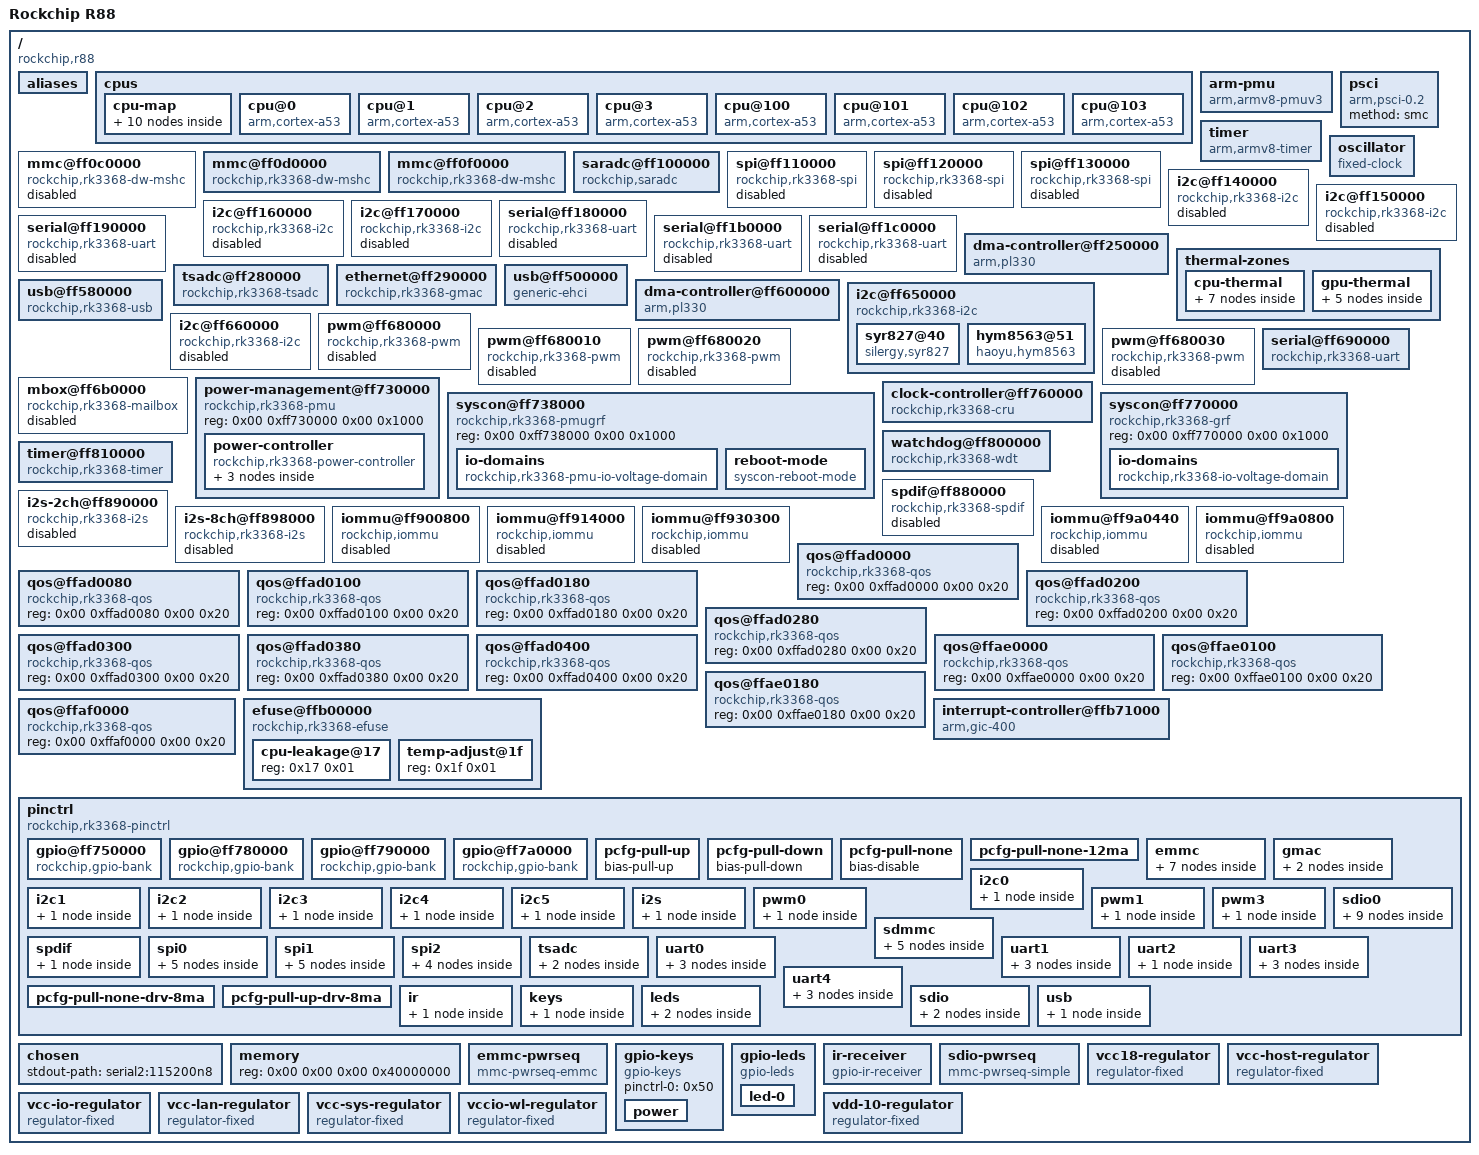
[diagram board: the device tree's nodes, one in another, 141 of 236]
/dts-v1/;

/ {
	compatible = "rockchip,r88\0rockchip,rk3368";
	interrupt-parent = <0x01>;
	#address-cells = <0x02>;
	#size-cells = <0x02>;
	model = "Rockchip R88";

	aliases {
		ethernet0 = "/ethernet@ff290000";
		i2c0 = "/i2c@ff650000";
		i2c1 = "/i2c@ff660000";
		i2c2 = "/i2c@ff140000";
		i2c3 = "/i2c@ff150000";
		i2c4 = "/i2c@ff160000";
		i2c5 = "/i2c@ff170000";
		serial0 = "/serial@ff180000";
		serial1 = "/serial@ff190000";
		serial2 = "/serial@ff690000";
		serial3 = "/serial@ff1b0000";
		serial4 = "/serial@ff1c0000";
		spi0 = "/spi@ff110000";
		spi1 = "/spi@ff120000";
		spi2 = "/spi@ff130000";
		mmc0 = "/mmc@ff0d0000";
		mmc1 = "/mmc@ff0f0000";
	};

	cpus {
		#address-cells = <0x02>;
		#size-cells = <0x00>;

		cpu-map {

			cluster0 {

				core0 {
					cpu = <0x02>;
				};

				core1 {
					cpu = <0x03>;
				};

				core2 {
					cpu = <0x04>;
				};

				core3 {
					cpu = <0x05>;
				};
			};

			cluster1 {

				core0 {
					cpu = <0x06>;
				};

				core1 {
					cpu = <0x07>;
				};

				core2 {
					cpu = <0x08>;
				};

				core3 {
					cpu = <0x09>;
				};
			};
		};

		cpu@0 {
			device_type = "cpu";
			compatible = "arm,cortex-a53";
			reg = <0x00 0x00>;
			enable-method = "psci";
			#cooling-cells = <0x02>;
			phandle = <0x06>;
		};

		cpu@1 {
			device_type = "cpu";
			compatible = "arm,cortex-a53";
			reg = <0x00 0x01>;
			enable-method = "psci";
			#cooling-cells = <0x02>;
			phandle = <0x07>;
		};

		cpu@2 {
			device_type = "cpu";
			compatible = "arm,cortex-a53";
			reg = <0x00 0x02>;
			enable-method = "psci";
			#cooling-cells = <0x02>;
			phandle = <0x08>;
		};

		cpu@3 {
			device_type = "cpu";
			compatible = "arm,cortex-a53";
			reg = <0x00 0x03>;
			enable-method = "psci";
			#cooling-cells = <0x02>;
			phandle = <0x09>;
		};

		cpu@100 {
			device_type = "cpu";
			compatible = "arm,cortex-a53";
			reg = <0x00 0x100>;
			enable-method = "psci";
			#cooling-cells = <0x02>;
			phandle = <0x02>;
		};

		cpu@101 {
			device_type = "cpu";
			compatible = "arm,cortex-a53";
			reg = <0x00 0x101>;
			enable-method = "psci";
			#cooling-cells = <0x02>;
			phandle = <0x03>;
		};

		cpu@102 {
			device_type = "cpu";
			compatible = "arm,cortex-a53";
			reg = <0x00 0x102>;
			enable-method = "psci";
			#cooling-cells = <0x02>;
			phandle = <0x04>;
		};

		cpu@103 {
			device_type = "cpu";
			compatible = "arm,cortex-a53";
			reg = <0x00 0x103>;
			enable-method = "psci";
			#cooling-cells = <0x02>;
			phandle = <0x05>;
		};
	};

	arm-pmu {
		compatible = "arm,armv8-pmuv3";
		interrupts = <0x00 0x70 0x04 0x00 0x71 0x04 0x00 0x72 0x04 0x00 0x73 0x04 0x00 0x74 0x04 0x00 0x75 0x04 0x00 0x76 0x04 0x00 0x77 0x04>;
		interrupt-affinity = <0x06 0x07 0x08 0x09 0x02 0x03 0x04 0x05>;
	};

	psci {
		compatible = "arm,psci-0.2";
		method = "smc";
	};

	timer {
		compatible = "arm,armv8-timer";
		interrupts = <0x01 0x0d 0xff04 0x01 0x0e 0xff04 0x01 0x0b 0xff04 0x01 0x0a 0xff04>;
	};

	oscillator {
		compatible = "fixed-clock";
		clock-frequency = <0x16e3600>;
		clock-output-names = "xin24m";
		#clock-cells = <0x00>;
		phandle = <0x58>;
	};

	mmc@ff0c0000 {
		compatible = "rockchip,rk3368-dw-mshc\0rockchip,rk3288-dw-mshc";
		reg = <0x00 0xff0c0000 0x00 0x4000>;
		max-frequency = <0x8f0d180>;
		clocks = <0x0a 0x1c8 0x0a 0x44 0x0a 0x72 0x0a 0x76>;
		clock-names = "biu\0ciu\0ciu-drive\0ciu-sample";
		fifo-depth = <0x100>;
		interrupts = <0x00 0x20 0x04>;
		resets = <0x0a 0x80>;
		reset-names = "reset";
		status = "disabled";
		phandle = <0x59>;
	};

	mmc@ff0d0000 {
		compatible = "rockchip,rk3368-dw-mshc\0rockchip,rk3288-dw-mshc";
		reg = <0x00 0xff0d0000 0x00 0x4000>;
		max-frequency = <0x8f0d180>;
		clocks = <0x0a 0x1c9 0x0a 0x45 0x0a 0x73 0x0a 0x77>;
		clock-names = "biu\0ciu\0ciu-drive\0ciu-sample";
		fifo-depth = <0x100>;
		interrupts = <0x00 0x21 0x04>;
		resets = <0x0a 0x81>;
		reset-names = "reset";
		status = "okay";
		assigned-clocks = <0x0a 0x45>;
		assigned-clock-parents = <0x0a 0x04>;
		bus-width = <0x04>;
		cap-sd-highspeed;
		cap-sdio-irq;
		keep-power-in-suspend;
		mmc-pwrseq = <0x0b>;
		non-removable;
		pinctrl-names = "default";
		pinctrl-0 = <0x0c 0x0d 0x0e>;
		vmmc-supply = <0x0f>;
		vqmmc-supply = <0x10>;
		phandle = <0x5a>;
	};

	mmc@ff0f0000 {
		compatible = "rockchip,rk3368-dw-mshc\0rockchip,rk3288-dw-mshc";
		reg = <0x00 0xff0f0000 0x00 0x4000>;
		max-frequency = <0x8f0d180>;
		clocks = <0x0a 0x1cb 0x0a 0x47 0x0a 0x75 0x0a 0x79>;
		clock-names = "biu\0ciu\0ciu-drive\0ciu-sample";
		fifo-depth = <0x100>;
		interrupts = <0x00 0x23 0x04>;
		resets = <0x0a 0x83>;
		reset-names = "reset";
		status = "okay";
		bus-width = <0x08>;
		cap-mmc-highspeed;
		mmc-pwrseq = <0x11>;
		non-removable;
		pinctrl-names = "default";
		pinctrl-0 = <0x12 0x13 0x14>;
		phandle = <0x5b>;
	};

	saradc@ff100000 {
		compatible = "rockchip,saradc";
		reg = <0x00 0xff100000 0x00 0x100>;
		interrupts = <0x00 0x24 0x04>;
		#io-channel-cells = <0x01>;
		clocks = <0x0a 0x49 0x0a 0x15b>;
		clock-names = "saradc\0apb_pclk";
		resets = <0x0a 0x57>;
		reset-names = "saradc-apb";
		status = "okay";
		vref-supply = <0x15>;
		phandle = <0x5c>;
	};

	spi@ff110000 {
		compatible = "rockchip,rk3368-spi\0rockchip,rk3066-spi";
		reg = <0x00 0xff110000 0x00 0x1000>;
		clocks = <0x0a 0x41 0x0a 0x152>;
		clock-names = "spiclk\0apb_pclk";
		interrupts = <0x00 0x2c 0x04>;
		pinctrl-names = "default";
		pinctrl-0 = <0x16 0x17 0x18 0x19>;
		#address-cells = <0x01>;
		#size-cells = <0x00>;
		status = "disabled";
		phandle = <0x5d>;
	};

	spi@ff120000 {
		compatible = "rockchip,rk3368-spi\0rockchip,rk3066-spi";
		reg = <0x00 0xff120000 0x00 0x1000>;
		clocks = <0x0a 0x42 0x0a 0x153>;
		clock-names = "spiclk\0apb_pclk";
		interrupts = <0x00 0x2d 0x04>;
		pinctrl-names = "default";
		pinctrl-0 = <0x1a 0x1b 0x1c 0x1d>;
		#address-cells = <0x01>;
		#size-cells = <0x00>;
		status = "disabled";
		phandle = <0x5e>;
	};

	spi@ff130000 {
		compatible = "rockchip,rk3368-spi\0rockchip,rk3066-spi";
		reg = <0x00 0xff130000 0x00 0x1000>;
		clocks = <0x0a 0x43 0x0a 0x154>;
		clock-names = "spiclk\0apb_pclk";
		interrupts = <0x00 0x29 0x04>;
		pinctrl-names = "default";
		pinctrl-0 = <0x1e 0x1f 0x20 0x21>;
		#address-cells = <0x01>;
		#size-cells = <0x00>;
		status = "disabled";
		phandle = <0x5f>;
	};

	i2c@ff140000 {
		compatible = "rockchip,rk3368-i2c\0rockchip,rk3288-i2c";
		reg = <0x00 0xff140000 0x00 0x1000>;
		interrupts = <0x00 0x3e 0x04>;
		#address-cells = <0x01>;
		#size-cells = <0x00>;
		clock-names = "i2c";
		clocks = <0x0a 0x14e>;
		pinctrl-names = "default";
		pinctrl-0 = <0x22>;
		status = "disabled";
		phandle = <0x60>;
	};

	i2c@ff150000 {
		compatible = "rockchip,rk3368-i2c\0rockchip,rk3288-i2c";
		reg = <0x00 0xff150000 0x00 0x1000>;
		interrupts = <0x00 0x3f 0x04>;
		#address-cells = <0x01>;
		#size-cells = <0x00>;
		clock-names = "i2c";
		clocks = <0x0a 0x14f>;
		pinctrl-names = "default";
		pinctrl-0 = <0x23>;
		status = "disabled";
		phandle = <0x61>;
	};

	i2c@ff160000 {
		compatible = "rockchip,rk3368-i2c\0rockchip,rk3288-i2c";
		reg = <0x00 0xff160000 0x00 0x1000>;
		interrupts = <0x00 0x40 0x04>;
		#address-cells = <0x01>;
		#size-cells = <0x00>;
		clock-names = "i2c";
		clocks = <0x0a 0x150>;
		pinctrl-names = "default";
		pinctrl-0 = <0x24>;
		status = "disabled";
		phandle = <0x62>;
	};

	i2c@ff170000 {
		compatible = "rockchip,rk3368-i2c\0rockchip,rk3288-i2c";
		reg = <0x00 0xff170000 0x00 0x1000>;
		interrupts = <0x00 0x41 0x04>;
		#address-cells = <0x01>;
		#size-cells = <0x00>;
		clock-names = "i2c";
		clocks = <0x0a 0x151>;
		pinctrl-names = "default";
		pinctrl-0 = <0x25>;
		status = "disabled";
		phandle = <0x63>;
	};

	serial@ff180000 {
		compatible = "rockchip,rk3368-uart\0snps,dw-apb-uart";
		reg = <0x00 0xff180000 0x00 0x100>;
		clock-frequency = <0x16e3600>;
		clocks = <0x0a 0x4d 0x0a 0x155>;
		clock-names = "baudclk\0apb_pclk";
		interrupts = <0x00 0x37 0x04>;
		reg-shift = <0x02>;
		reg-io-width = <0x04>;
		status = "disabled";
		phandle = <0x64>;
	};

	serial@ff190000 {
		compatible = "rockchip,rk3368-uart\0snps,dw-apb-uart";
		reg = <0x00 0xff190000 0x00 0x100>;
		clock-frequency = <0x16e3600>;
		clocks = <0x0a 0x4e 0x0a 0x156>;
		clock-names = "baudclk\0apb_pclk";
		interrupts = <0x00 0x38 0x04>;
		reg-shift = <0x02>;
		reg-io-width = <0x04>;
		status = "disabled";
		phandle = <0x65>;
	};

	serial@ff1b0000 {
		compatible = "rockchip,rk3368-uart\0snps,dw-apb-uart";
		reg = <0x00 0xff1b0000 0x00 0x100>;
		clock-frequency = <0x16e3600>;
		clocks = <0x0a 0x50 0x0a 0x158>;
		clock-names = "baudclk\0apb_pclk";
		interrupts = <0x00 0x3a 0x04>;
		reg-shift = <0x02>;
		reg-io-width = <0x04>;
		status = "disabled";
		phandle = <0x66>;
	};

	serial@ff1c0000 {
		compatible = "rockchip,rk3368-uart\0snps,dw-apb-uart";
		reg = <0x00 0xff1c0000 0x00 0x100>;
		clock-frequency = <0x16e3600>;
		clocks = <0x0a 0x51 0x0a 0x159>;
		clock-names = "baudclk\0apb_pclk";
		interrupts = <0x00 0x3b 0x04>;
		reg-shift = <0x02>;
		reg-io-width = <0x04>;
		status = "disabled";
		phandle = <0x67>;
	};

	dma-controller@ff250000 {
		compatible = "arm,pl330\0arm,primecell";
		reg = <0x00 0xff250000 0x00 0x4000>;
		interrupts = <0x00 0x02 0x04 0x00 0x03 0x04>;
		#dma-cells = <0x01>;
		arm,pl330-broken-no-flushp;
		arm,pl330-periph-burst;
		clocks = <0x0a 0xc3>;
		clock-names = "apb_pclk";
		phandle = <0x68>;
	};

	thermal-zones {

		cpu-thermal {
			polling-delay-passive = <0x64>;
			polling-delay = <0x1388>;
			thermal-sensors = <0x26 0x00>;
			phandle = <0x69>;

			trips {

				cpu_alert0 {
					temperature = <0x124f8>;
					hysteresis = <0x7d0>;
					type = "passive";
					phandle = <0x27>;
				};

				cpu_alert1 {
					temperature = <0x13880>;
					hysteresis = <0x7d0>;
					type = "passive";
					phandle = <0x28>;
				};

				cpu_crit {
					temperature = <0x17318>;
					hysteresis = <0x7d0>;
					type = "critical";
					phandle = <0x6a>;
				};
			};

			cooling-maps {

				map0 {
					trip = <0x27>;
					cooling-device = <0x02 0xffffffff 0xffffffff 0x03 0xffffffff 0xffffffff 0x04 0xffffffff 0xffffffff 0x05 0xffffffff 0xffffffff>;
				};

				map1 {
					trip = <0x28>;
					cooling-device = <0x06 0xffffffff 0xffffffff 0x07 0xffffffff 0xffffffff 0x08 0xffffffff 0xffffffff 0x09 0xffffffff 0xffffffff>;
				};
			};
		};

		gpu-thermal {
			polling-delay-passive = <0x64>;
			polling-delay = <0x1388>;
			thermal-sensors = <0x26 0x01>;
			phandle = <0x6b>;

			trips {

				gpu_alert0 {
					temperature = <0x13880>;
					hysteresis = <0x7d0>;
					type = "passive";
					phandle = <0x29>;
				};

				gpu_crit {
					temperature = <0x1c138>;
					hysteresis = <0x7d0>;
					type = "critical";
					phandle = <0x6c>;
				};
			};

			cooling-maps {

				map0 {
					trip = <0x29>;
					cooling-device = <0x02 0xffffffff 0xffffffff 0x03 0xffffffff 0xffffffff 0x04 0xffffffff 0xffffffff 0x05 0xffffffff 0xffffffff>;
				};
			};
		};
	};

	tsadc@ff280000 {
		compatible = "rockchip,rk3368-tsadc";
		reg = <0x00 0xff280000 0x00 0x100>;
		interrupts = <0x00 0x25 0x04>;
		clocks = <0x0a 0x48 0x0a 0x15a>;
		clock-names = "tsadc\0apb_pclk";
		resets = <0x0a 0x9f>;
		reset-names = "tsadc-apb";
		pinctrl-names = "init\0default\0sleep";
		pinctrl-0 = <0x2a>;
		pinctrl-1 = <0x2b>;
		pinctrl-2 = <0x2a>;
		#thermal-sensor-cells = <0x01>;
		rockchip,hw-tshut-temp = <0x17318>;
		status = "okay";
		rockchip,hw-tshut-mode = <0x00>;
		rockchip,hw-tshut-polarity = <0x00>;
		phandle = <0x26>;
	};

	ethernet@ff290000 {
		compatible = "rockchip,rk3368-gmac";
		reg = <0x00 0xff290000 0x00 0x10000>;
		interrupts = <0x00 0x1b 0x04>;
		interrupt-names = "macirq";
		rockchip,grf = <0x2c>;
		clocks = <0x0a 0x7f 0x0a 0x66 0x0a 0x67 0x0a 0x63 0x0a 0x80 0x0a 0xc5 0x0a 0x15d>;
		clock-names = "stmmaceth\0mac_clk_rx\0mac_clk_tx\0clk_mac_ref\0clk_mac_refout\0aclk_mac\0pclk_mac";
		status = "okay";
		phy-supply = <0x2d>;
		phy-mode = "rmii";
		clock_in_out = "output";
		snps,reset-gpio = <0x2e 0x0c 0x00>;
		snps,reset-active-low;
		snps,reset-delays-us = <0x00 0x2710 0xf4240>;
		pinctrl-names = "default";
		pinctrl-0 = <0x2f>;
		tx_delay = <0x30>;
		rx_delay = <0x10>;
		phandle = <0x6d>;
	};

	usb@ff500000 {
		compatible = "generic-ehci";
		reg = <0x00 0xff500000 0x00 0x100>;
		interrupts = <0x00 0x18 0x04>;
		clocks = <0x0a 0x1c2>;
		status = "okay";
		phandle = <0x6e>;
	};

	usb@ff580000 {
		compatible = "rockchip,rk3368-usb\0rockchip,rk3066-usb\0snps,dwc2";
		reg = <0x00 0xff580000 0x00 0x40000>;
		interrupts = <0x00 0x17 0x04>;
		clocks = <0x0a 0x1c1>;
		clock-names = "otg";
		dr_mode = "host";
		g-np-tx-fifo-size = <0x10>;
		g-rx-fifo-size = <0x113>;
		g-tx-fifo-size = <0x100 0x80 0x80 0x40 0x40 0x20>;
		status = "okay";
		phandle = <0x6f>;
	};

	dma-controller@ff600000 {
		compatible = "arm,pl330\0arm,primecell";
		reg = <0x00 0xff600000 0x00 0x4000>;
		interrupts = <0x00 0x00 0x04 0x00 0x01 0x04>;
		#dma-cells = <0x01>;
		arm,pl330-broken-no-flushp;
		arm,pl330-periph-burst;
		clocks = <0x0a 0xc2>;
		clock-names = "apb_pclk";
		phandle = <0x44>;
	};

	i2c@ff650000 {
		compatible = "rockchip,rk3368-i2c\0rockchip,rk3288-i2c";
		reg = <0x00 0xff650000 0x00 0x1000>;
		clocks = <0x0a 0x14c>;
		clock-names = "i2c";
		interrupts = <0x00 0x3c 0x04>;
		pinctrl-names = "default";
		pinctrl-0 = <0x30>;
		#address-cells = <0x01>;
		#size-cells = <0x00>;
		status = "okay";
		phandle = <0x70>;

		syr827@40 {
			compatible = "silergy,syr827";
			reg = <0x40>;
			fcs,suspend-voltage-selector = <0x01>;
			regulator-name = "vdd_cpu";
			regulator-enable-ramp-delay = <0x12c>;
			regulator-min-microvolt = <0xadf34>;
			regulator-max-microvolt = <0x16e360>;
			regulator-ramp-delay = <0x1f40>;
			regulator-always-on;
			regulator-boot-on;
			vin-supply = <0x31>;
			phandle = <0x71>;
		};

		hym8563@51 {
			compatible = "haoyu,hym8563";
			reg = <0x51>;
			#clock-cells = <0x00>;
			clock-frequency = <0x8000>;
			clock-output-names = "xin32k";
			phandle = <0x54>;
		};
	};

	i2c@ff660000 {
		compatible = "rockchip,rk3368-i2c\0rockchip,rk3288-i2c";
		reg = <0x00 0xff660000 0x00 0x1000>;
		interrupts = <0x00 0x3d 0x04>;
		#address-cells = <0x01>;
		#size-cells = <0x00>;
		clock-names = "i2c";
		clocks = <0x0a 0x14d>;
		pinctrl-names = "default";
		pinctrl-0 = <0x32>;
		status = "disabled";
		phandle = <0x72>;
	};

	pwm@ff680000 {
		compatible = "rockchip,rk3368-pwm\0rockchip,rk3288-pwm";
		reg = <0x00 0xff680000 0x00 0x10>;
		#pwm-cells = <0x03>;
		pinctrl-names = "default";
		pinctrl-0 = <0x33>;
		clocks = <0x0a 0x15f>;
		status = "disabled";
		phandle = <0x73>;
	};

	pwm@ff680010 {
		compatible = "rockchip,rk3368-pwm\0rockchip,rk3288-pwm";
		reg = <0x00 0xff680010 0x00 0x10>;
		#pwm-cells = <0x03>;
		pinctrl-names = "default";
		pinctrl-0 = <0x34>;
		clocks = <0x0a 0x15f>;
		status = "disabled";
		phandle = <0x74>;
	};

	pwm@ff680020 {
		compatible = "rockchip,rk3368-pwm\0rockchip,rk3288-pwm";
		reg = <0x00 0xff680020 0x00 0x10>;
		#pwm-cells = <0x03>;
		clocks = <0x0a 0x15f>;
		status = "disabled";
		phandle = <0x75>;
	};

	pwm@ff680030 {
		compatible = "rockchip,rk3368-pwm\0rockchip,rk3288-pwm";
		reg = <0x00 0xff680030 0x00 0x10>;
		#pwm-cells = <0x03>;
		pinctrl-names = "default";
		pinctrl-0 = <0x35>;
		clocks = <0x0a 0x15f>;
		status = "disabled";
		phandle = <0x76>;
	};

	serial@ff690000 {
		compatible = "rockchip,rk3368-uart\0snps,dw-apb-uart";
		reg = <0x00 0xff690000 0x00 0x100>;
		clocks = <0x0a 0x4f 0x0a 0x157>;
		clock-names = "baudclk\0apb_pclk";
		interrupts = <0x00 0x39 0x04>;
		pinctrl-names = "default";
		pinctrl-0 = <0x36>;
		reg-shift = <0x02>;
		reg-io-width = <0x04>;
		status = "okay";
		phandle = <0x77>;
	};

	mbox@ff6b0000 {
		compatible = "rockchip,rk3368-mailbox";
		reg = <0x00 0xff6b0000 0x00 0x1000>;
		interrupts = <0x00 0x92 0x04 0x00 0x93 0x04 0x00 0x94 0x04 0x00 0x95 0x04>;
		clocks = <0x0a 0x145>;
		clock-names = "pclk_mailbox";
		#mbox-cells = <0x01>;
		status = "disabled";
		phandle = <0x78>;
	};

	power-management@ff730000 {
		compatible = "rockchip,rk3368-pmu\0syscon\0simple-mfd";
		reg = <0x00 0xff730000 0x00 0x1000>;
		phandle = <0x79>;

		power-controller {
			compatible = "rockchip,rk3368-power-controller";
			#power-domain-cells = <0x01>;
			#address-cells = <0x01>;
			#size-cells = <0x00>;
			phandle = <0x47>;

			power-domain@12 {
				reg = <0x0c>;
				clocks = <0x0a 0xca 0x0a 0xcd 0x0a 0xcc 0x0a 0xc8 0x0a 0xc6 0x0a 0xc7 0x0a 0xbe 0x0a 0x1d4 0x0a 0x1d5 0x0a 0x1d6 0x0a 0x1d9 0x0a 0x1d1 0x0a 0x1db 0x0a 0x163 0x0a 0x168 0x0a 0x167 0x0a 0x16e 0x0a 0x16f 0x0a 0x172 0x0a 0x173 0x0a 0x166 0x0a 0x164 0x0a 0x64 0x0a 0x68 0x0a 0x69 0x0a 0x6c 0x0a 0x6b 0x0a 0x6a 0x0a 0x6e 0x0a 0x6d>;
				pm_qos = <0x37 0x38 0x39 0x3a 0x3b 0x3c 0x3d 0x3e 0x3f>;
				#power-domain-cells = <0x00>;
			};

			power-domain@14 {
				reg = <0x0e>;
				clocks = <0x0a 0xd0 0x0a 0x1dc 0x0a 0x6f 0x0a 0x70>;
				pm_qos = <0x40 0x41 0x42>;
				#power-domain-cells = <0x00>;
			};

			power-domain@16 {
				reg = <0x10>;
				clocks = <0x0a 0xc1 0x0a 0xc0 0x0a 0x40>;
				pm_qos = <0x43>;
				#power-domain-cells = <0x00>;
			};
		};
	};

	syscon@ff738000 {
		compatible = "rockchip,rk3368-pmugrf\0syscon\0simple-mfd";
		reg = <0x00 0xff738000 0x00 0x1000>;
		phandle = <0x48>;

		io-domains {
			compatible = "rockchip,rk3368-pmu-io-voltage-domain";
			status = "okay";
			pmu-supply = <0x0f>;
			vop-supply = <0x0f>;
			phandle = <0x7a>;
		};

		reboot-mode {
			compatible = "syscon-reboot-mode";
			offset = <0x200>;
			mode-normal = <0x5242c300>;
			mode-recovery = <0x5242c303>;
			mode-bootloader = <0x5242c309>;
			mode-loader = <0x5242c301>;
		};
	};

	clock-controller@ff760000 {
		compatible = "rockchip,rk3368-cru";
		reg = <0x00 0xff760000 0x00 0x1000>;
		rockchip,grf = <0x2c>;
		#clock-cells = <0x01>;
		#reset-cells = <0x01>;
		phandle = <0x0a>;
	};

	syscon@ff770000 {
		compatible = "rockchip,rk3368-grf\0syscon\0simple-mfd";
		reg = <0x00 0xff770000 0x00 0x1000>;
		phandle = <0x2c>;

		io-domains {
			compatible = "rockchip,rk3368-io-voltage-domain";
			status = "okay";
			audio-supply = <0x0f>;
			gpio30-supply = <0x0f>;
			gpio1830-supply = <0x0f>;
			wifi-supply = <0x10>;
			phandle = <0x7b>;
		};
	};

	watchdog@ff800000 {
		compatible = "rockchip,rk3368-wdt\0snps,dw-wdt";
		reg = <0x00 0xff800000 0x00 0x100>;
		clocks = <0x0a 0x170>;
		interrupts = <0x00 0x4f 0x04>;
		status = "okay";
		phandle = <0x7c>;
	};

	timer@ff810000 {
		compatible = "rockchip,rk3368-timer\0rockchip,rk3288-timer";
		reg = <0x00 0xff810000 0x00 0x20>;
		interrupts = <0x00 0x42 0x04>;
		clocks = <0x0a 0x161 0x0a 0x55>;
		clock-names = "pclk\0timer";
		phandle = <0x7d>;
	};

	spdif@ff880000 {
		compatible = "rockchip,rk3368-spdif";
		reg = <0x00 0xff880000 0x00 0x1000>;
		interrupts = <0x00 0x36 0x04>;
		clocks = <0x0a 0x53 0x0a 0x1d0>;
		clock-names = "mclk\0hclk";
		dmas = <0x44 0x03>;
		dma-names = "tx";
		pinctrl-names = "default";
		pinctrl-0 = <0x45>;
		status = "disabled";
		phandle = <0x7e>;
	};

	i2s-2ch@ff890000 {
		compatible = "rockchip,rk3368-i2s\0rockchip,rk3066-i2s";
		reg = <0x00 0xff890000 0x00 0x1000>;
		interrupts = <0x00 0x28 0x04>;
		clock-names = "i2s_clk\0i2s_hclk";
		clocks = <0x0a 0x54 0x0a 0x1ce>;
		dmas = <0x44 0x06 0x44 0x07>;
		dma-names = "tx\0rx";
		status = "disabled";
		phandle = <0x7f>;
	};

	i2s-8ch@ff898000 {
		compatible = "rockchip,rk3368-i2s\0rockchip,rk3066-i2s";
		reg = <0x00 0xff898000 0x00 0x1000>;
		interrupts = <0x00 0x35 0x04>;
		clock-names = "i2s_clk\0i2s_hclk";
		clocks = <0x0a 0x52 0x0a 0x1cf>;
		dmas = <0x44 0x00 0x44 0x01>;
		dma-names = "tx\0rx";
		pinctrl-names = "default";
		pinctrl-0 = <0x46>;
		status = "disabled";
		phandle = <0x80>;
	};

	iommu@ff900800 {
		compatible = "rockchip,iommu";
		reg = <0x00 0xff900800 0x00 0x100>;
		interrupts = <0x00 0x11 0x04>;
		clocks = <0x0a 0xca 0x0a 0x1d4>;
		clock-names = "aclk\0iface";
		power-domains = <0x47 0x0c>;
		#iommu-cells = <0x00>;
		status = "disabled";
		phandle = <0x81>;
	};

	iommu@ff914000 {
		compatible = "rockchip,iommu";
		reg = <0x00 0xff914000 0x00 0x100 0x00 0xff915000 0x00 0x100>;
		interrupts = <0x00 0x0e 0x04>;
		clocks = <0x0a 0xcd 0x0a 0x1d5>;
		clock-names = "aclk\0iface";
		#iommu-cells = <0x00>;
		power-domains = <0x47 0x0c>;
		rockchip,disable-mmu-reset;
		status = "disabled";
		phandle = <0x82>;
	};

	iommu@ff930300 {
		compatible = "rockchip,iommu";
		reg = <0x00 0xff930300 0x00 0x100>;
		interrupts = <0x00 0x0f 0x04>;
		clocks = <0x0a 0xc6 0x0a 0x1d1>;
		clock-names = "aclk\0iface";
		power-domains = <0x47 0x0c>;
		#iommu-cells = <0x00>;
		status = "disabled";
		phandle = <0x83>;
	};

	iommu@ff9a0440 {
		compatible = "rockchip,iommu";
		reg = <0x00 0xff9a0440 0x00 0x40 0x00 0xff9a0480 0x00 0x40>;
		interrupts = <0x00 0x0c 0x04>;
		clocks = <0x0a 0xd0 0x0a 0x1dc>;
		clock-names = "aclk\0iface";
		#iommu-cells = <0x00>;
		status = "disabled";
		phandle = <0x84>;
	};

	iommu@ff9a0800 {
		compatible = "rockchip,iommu";
		reg = <0x00 0xff9a0800 0x00 0x100>;
		interrupts = <0x00 0x09 0x04 0x00 0x0a 0x04>;
		clocks = <0x0a 0xd0 0x0a 0x1dc>;
		clock-names = "aclk\0iface";
		#iommu-cells = <0x00>;
		status = "disabled";
		phandle = <0x85>;
	};

	qos@ffad0000 {
		compatible = "rockchip,rk3368-qos\0syscon";
		reg = <0x00 0xffad0000 0x00 0x20>;
		phandle = <0x37>;
	};

	qos@ffad0080 {
		compatible = "rockchip,rk3368-qos\0syscon";
		reg = <0x00 0xffad0080 0x00 0x20>;
		phandle = <0x38>;
	};

	qos@ffad0100 {
		compatible = "rockchip,rk3368-qos\0syscon";
		reg = <0x00 0xffad0100 0x00 0x20>;
		phandle = <0x39>;
	};

	qos@ffad0180 {
		compatible = "rockchip,rk3368-qos\0syscon";
		reg = <0x00 0xffad0180 0x00 0x20>;
		phandle = <0x3a>;
	};

	qos@ffad0200 {
		compatible = "rockchip,rk3368-qos\0syscon";
		reg = <0x00 0xffad0200 0x00 0x20>;
		phandle = <0x3b>;
	};

	qos@ffad0280 {
		compatible = "rockchip,rk3368-qos\0syscon";
		reg = <0x00 0xffad0280 0x00 0x20>;
		phandle = <0x3c>;
	};

	qos@ffad0300 {
		compatible = "rockchip,rk3368-qos\0syscon";
		reg = <0x00 0xffad0300 0x00 0x20>;
		phandle = <0x3d>;
	};

	qos@ffad0380 {
		compatible = "rockchip,rk3368-qos\0syscon";
		reg = <0x00 0xffad0380 0x00 0x20>;
		phandle = <0x3e>;
	};

	qos@ffad0400 {
		compatible = "rockchip,rk3368-qos\0syscon";
		reg = <0x00 0xffad0400 0x00 0x20>;
		phandle = <0x3f>;
	};

	qos@ffae0000 {
		compatible = "rockchip,rk3368-qos\0syscon";
		reg = <0x00 0xffae0000 0x00 0x20>;
		phandle = <0x40>;
	};

	qos@ffae0100 {
		compatible = "rockchip,rk3368-qos\0syscon";
		reg = <0x00 0xffae0100 0x00 0x20>;
		phandle = <0x41>;
	};

	qos@ffae0180 {
		compatible = "rockchip,rk3368-qos\0syscon";
		reg = <0x00 0xffae0180 0x00 0x20>;
		phandle = <0x42>;
	};

	qos@ffaf0000 {
		compatible = "rockchip,rk3368-qos\0syscon";
		reg = <0x00 0xffaf0000 0x00 0x20>;
		phandle = <0x43>;
	};

	efuse@ffb00000 {
		compatible = "rockchip,rk3368-efuse";
		reg = <0x00 0xffb00000 0x00 0x20>;
		#address-cells = <0x01>;
		#size-cells = <0x01>;
		clocks = <0x0a 0x171>;
		clock-names = "pclk_efuse";
		phandle = <0x86>;

		cpu-leakage@17 {
			reg = <0x17 0x01>;
			phandle = <0x87>;
		};

		temp-adjust@1f {
			reg = <0x1f 0x01>;
			phandle = <0x88>;
		};
	};

	interrupt-controller@ffb71000 {
		compatible = "arm,gic-400";
		interrupt-controller;
		#interrupt-cells = <0x03>;
		#address-cells = <0x00>;
		reg = <0x00 0xffb71000 0x00 0x1000 0x00 0xffb72000 0x00 0x2000 0x00 0xffb74000 0x00 0x2000 0x00 0xffb76000 0x00 0x2000>;
		interrupts = <0x01 0x09 0xff04>;
		phandle = <0x01>;
	};

	pinctrl {
		compatible = "rockchip,rk3368-pinctrl";
		rockchip,grf = <0x2c>;
		rockchip,pmu = <0x48>;
		#address-cells = <0x02>;
		#size-cells = <0x02>;
		ranges;
		phandle = <0x89>;

		gpio@ff750000 {
			compatible = "rockchip,gpio-bank";
			reg = <0x00 0xff750000 0x00 0x100>;
			clocks = <0x0a 0x140>;
			interrupts = <0x00 0x51 0x04>;
			gpio-controller;
			#gpio-cells = <0x02>;
			interrupt-controller;
			#interrupt-cells = <0x02>;
			phandle = <0x51>;
		};

		gpio@ff780000 {
			compatible = "rockchip,gpio-bank";
			reg = <0x00 0xff780000 0x00 0x100>;
			clocks = <0x0a 0x141>;
			interrupts = <0x00 0x52 0x04>;
			gpio-controller;
			#gpio-cells = <0x02>;
			interrupt-controller;
			#interrupt-cells = <0x02>;
			phandle = <0x8a>;
		};

		gpio@ff790000 {
			compatible = "rockchip,gpio-bank";
			reg = <0x00 0xff790000 0x00 0x100>;
			clocks = <0x0a 0x142>;
			interrupts = <0x00 0x53 0x04>;
			gpio-controller;
			#gpio-cells = <0x02>;
			interrupt-controller;
			#interrupt-cells = <0x02>;
			phandle = <0x4f>;
		};

		gpio@ff7a0000 {
			compatible = "rockchip,gpio-bank";
			reg = <0x00 0xff7a0000 0x00 0x100>;
			clocks = <0x0a 0x143>;
			interrupts = <0x00 0x54 0x04>;
			gpio-controller;
			#gpio-cells = <0x02>;
			interrupt-controller;
			#interrupt-cells = <0x02>;
			phandle = <0x2e>;
		};

		pcfg-pull-up {
			bias-pull-up;
			phandle = <0x4b>;
		};

		pcfg-pull-down {
			bias-pull-down;
			phandle = <0x8b>;
		};

		pcfg-pull-none {
			bias-disable;
			phandle = <0x4c>;
		};

		pcfg-pull-none-12ma {
			bias-disable;
			drive-strength = <0x0c>;
			phandle = <0x4d>;
		};

		emmc {

			emmc-clk {
				rockchip,pins = <0x02 0x04 0x02 0x49>;
				phandle = <0x12>;
			};

			emmc-cmd {
				rockchip,pins = <0x01 0x1a 0x02 0x4a>;
				phandle = <0x13>;
			};

			emmc-pwr {
				rockchip,pins = <0x01 0x1b 0x02 0x4b>;
				phandle = <0x8c>;
			};

			emmc-bus1 {
				rockchip,pins = <0x01 0x12 0x02 0x4b>;
				phandle = <0x8d>;
			};

			emmc-bus4 {
				rockchip,pins = <0x01 0x12 0x02 0x4b 0x01 0x13 0x02 0x4b 0x01 0x14 0x02 0x4b 0x01 0x15 0x02 0x4b>;
				phandle = <0x8e>;
			};

			emmc-bus8 {
				rockchip,pins = <0x01 0x12 0x02 0x4a 0x01 0x13 0x02 0x4a 0x01 0x14 0x02 0x4a 0x01 0x15 0x02 0x4a 0x01 0x16 0x02 0x4a 0x01 0x17 0x02 0x4a 0x01 0x18 0x02 0x4a 0x01 0x19 0x02 0x4a>;
				phandle = <0x14>;
			};

			emmc-reset {
				rockchip,pins = <0x02 0x03 0x00 0x4c>;
				phandle = <0x4e>;
			};
		};

		gmac {

			rgmii-pins {
				rockchip,pins = <0x03 0x16 0x01 0x4c 0x03 0x18 0x01 0x4c 0x03 0x13 0x01 0x4c 0x03 0x08 0x01 0x4d 0x03 0x09 0x01 0x4d 0x03 0x0a 0x01 0x4d 0x03 0x0e 0x01 0x4d 0x03 0x1c 0x01 0x4d 0x03 0x0d 0x01 0x4d 0x03 0x0f 0x01 0x4c 0x03 0x10 0x01 0x4c 0x03 0x11 0x01 0x4c 0x03 0x12 0x01 0x4c 0x03 0x19 0x01 0x4c 0x03 0x14 0x01 0x4c>;
				phandle = <0x8f>;
			};

			rmii-pins {
				rockchip,pins = <0x03 0x16 0x01 0x4c 0x03 0x18 0x01 0x4c 0x03 0x13 0x01 0x4c 0x03 0x08 0x01 0x4d 0x03 0x09 0x01 0x4d 0x03 0x0d 0x01 0x4d 0x03 0x0f 0x01 0x4c 0x03 0x10 0x01 0x4c 0x03 0x14 0x01 0x4c 0x03 0x15 0x01 0x4c>;
				phandle = <0x2f>;
			};
		};

		i2c0 {

			i2c0-xfer {
				rockchip,pins = <0x00 0x06 0x01 0x4c 0x00 0x07 0x01 0x4c>;
				phandle = <0x30>;
			};
		};

		i2c1 {

			i2c1-xfer {
				rockchip,pins = <0x02 0x15 0x01 0x4c 0x02 0x16 0x01 0x4c>;
				phandle = <0x32>;
			};
		};

		i2c2 {

			i2c2-xfer {
				rockchip,pins = <0x00 0x09 0x02 0x4c 0x03 0x1f 0x02 0x4c>;
				phandle = <0x22>;
			};
		};

		i2c3 {

			i2c3-xfer {
				rockchip,pins = <0x01 0x10 0x01 0x4c 0x01 0x11 0x01 0x4c>;
				phandle = <0x23>;
			};
		};

		i2c4 {

			i2c4-xfer {
				rockchip,pins = <0x03 0x18 0x02 0x4c 0x03 0x19 0x02 0x4c>;
				phandle = <0x24>;
			};
		};

		i2c5 {

			i2c5-xfer {
				rockchip,pins = <0x03 0x1a 0x02 0x4c 0x03 0x1b 0x02 0x4c>;
				phandle = <0x25>;
			};
		};

		i2s {

			i2s-8ch-bus {
				rockchip,pins = <0x02 0x0c 0x01 0x4c 0x02 0x0d 0x01 0x4c 0x02 0x0e 0x01 0x4c 0x02 0x0f 0x01 0x4c 0x02 0x10 0x01 0x4c 0x02 0x11 0x01 0x4c 0x02 0x12 0x01 0x4c 0x02 0x13 0x01 0x4c 0x02 0x14 0x01 0x4c>;
				phandle = <0x46>;
			};
		};

		pwm0 {

			pwm0-pin {
				rockchip,pins = <0x03 0x08 0x02 0x4c>;
				phandle = <0x33>;
			};
		};

		pwm1 {

			pwm1-pin {
				rockchip,pins = <0x00 0x08 0x02 0x4c>;
				phandle = <0x34>;
			};
		};

		pwm3 {

			pwm3-pin {
				rockchip,pins = <0x03 0x1d 0x03 0x4c>;
				phandle = <0x35>;
			};
		};

		sdio0 {

			sdio0-bus1 {
				rockchip,pins = <0x02 0x1c 0x01 0x4b>;
				phandle = <0x90>;
			};

			sdio0-bus4 {
				rockchip,pins = <0x02 0x1c 0x01 0x4b 0x02 0x1d 0x01 0x4b 0x02 0x1e 0x01 0x4b 0x02 0x1f 0x01 0x4b>;
				phandle = <0x0e>;
			};

			sdio0-cmd {
				rockchip,pins = <0x03 0x00 0x01 0x4b>;
				phandle = <0x0d>;
			};

			sdio0-clk {
				rockchip,pins = <0x03 0x01 0x01 0x4c>;
				phandle = <0x0c>;
			};

			sdio0-cd {
				rockchip,pins = <0x03 0x02 0x01 0x4b>;
				phandle = <0x91>;
			};

			sdio0-wp {
				rockchip,pins = <0x03 0x03 0x01 0x4b>;
				phandle = <0x92>;
			};

			sdio0-pwr {
				rockchip,pins = <0x03 0x04 0x01 0x4b>;
				phandle = <0x93>;
			};

			sdio0-bkpwr {
				rockchip,pins = <0x03 0x05 0x01 0x4b>;
				phandle = <0x94>;
			};

			sdio0-int {
				rockchip,pins = <0x03 0x06 0x01 0x4b>;
				phandle = <0x95>;
			};
		};

		sdmmc {

			sdmmc-clk {
				rockchip,pins = <0x02 0x09 0x01 0x4c>;
				phandle = <0x96>;
			};

			sdmmc-cmd {
				rockchip,pins = <0x02 0x0a 0x01 0x4b>;
				phandle = <0x97>;
			};

			sdmmc-cd {
				rockchip,pins = <0x02 0x0b 0x01 0x4b>;
				phandle = <0x98>;
			};

			sdmmc-bus1 {
				rockchip,pins = <0x02 0x05 0x01 0x4b>;
				phandle = <0x99>;
			};

			sdmmc-bus4 {
				rockchip,pins = <0x02 0x05 0x01 0x4b 0x02 0x06 0x01 0x4b 0x02 0x07 0x01 0x4b 0x02 0x08 0x01 0x4b>;
				phandle = <0x9a>;
			};
		};

		spdif {

			spdif-tx {
				rockchip,pins = <0x02 0x17 0x01 0x4c>;
				phandle = <0x45>;
			};
		};

		spi0 {

			spi0-clk {
				rockchip,pins = <0x01 0x1d 0x02 0x4b>;
				phandle = <0x16>;
			};

			spi0-cs0 {
				rockchip,pins = <0x01 0x18 0x03 0x4b>;
				phandle = <0x19>;
			};

			spi0-cs1 {
				rockchip,pins = <0x01 0x19 0x03 0x4b>;
				phandle = <0x9b>;
			};

			spi0-tx {
				rockchip,pins = <0x01 0x17 0x03 0x4b>;
				phandle = <0x17>;
			};

			spi0-rx {
				rockchip,pins = <0x01 0x16 0x03 0x4b>;
				phandle = <0x18>;
			};
		};

		spi1 {

			spi1-clk {
				rockchip,pins = <0x01 0x0e 0x02 0x4b>;
				phandle = <0x1a>;
			};

			spi1-cs0 {
				rockchip,pins = <0x01 0x0f 0x02 0x4b>;
				phandle = <0x1d>;
			};

			spi1-cs1 {
				rockchip,pins = <0x03 0x1c 0x02 0x4b>;
				phandle = <0x9c>;
			};

			spi1-rx {
				rockchip,pins = <0x01 0x10 0x02 0x4b>;
				phandle = <0x1c>;
			};

			spi1-tx {
				rockchip,pins = <0x01 0x11 0x02 0x4b>;
				phandle = <0x1b>;
			};
		};

		spi2 {

			spi2-clk {
				rockchip,pins = <0x00 0x0c 0x02 0x4b>;
				phandle = <0x1e>;
			};

			spi2-cs0 {
				rockchip,pins = <0x00 0x0d 0x02 0x4b>;
				phandle = <0x21>;
			};

			spi2-rx {
				rockchip,pins = <0x00 0x0a 0x02 0x4b>;
				phandle = <0x20>;
			};

			spi2-tx {
				rockchip,pins = <0x00 0x0b 0x02 0x4b>;
				phandle = <0x1f>;
			};
		};

		tsadc {

			otp-pin {
				rockchip,pins = <0x00 0x03 0x00 0x4c>;
				phandle = <0x2a>;
			};

			otp-out {
				rockchip,pins = <0x00 0x03 0x01 0x4c>;
				phandle = <0x2b>;
			};
		};

		uart0 {

			uart0-xfer {
				rockchip,pins = <0x02 0x18 0x01 0x4b 0x02 0x19 0x01 0x4c>;
				phandle = <0x9d>;
			};

			uart0-cts {
				rockchip,pins = <0x02 0x1a 0x01 0x4c>;
				phandle = <0x9e>;
			};

			uart0-rts {
				rockchip,pins = <0x02 0x1b 0x01 0x4c>;
				phandle = <0x9f>;
			};
		};

		uart1 {

			uart1-xfer {
				rockchip,pins = <0x00 0x14 0x03 0x4b 0x00 0x15 0x03 0x4c>;
				phandle = <0xa0>;
			};

			uart1-cts {
				rockchip,pins = <0x00 0x16 0x03 0x4c>;
				phandle = <0xa1>;
			};

			uart1-rts {
				rockchip,pins = <0x00 0x17 0x03 0x4c>;
				phandle = <0xa2>;
			};
		};

		uart2 {

			uart2-xfer {
				rockchip,pins = <0x02 0x06 0x02 0x4b 0x02 0x05 0x02 0x4c>;
				phandle = <0x36>;
			};
		};

		uart3 {

			uart3-xfer {
				rockchip,pins = <0x03 0x1d 0x02 0x4b 0x03 0x1e 0x03 0x4c>;
				phandle = <0xa3>;
			};

			uart3-cts {
				rockchip,pins = <0x03 0x10 0x02 0x4c>;
				phandle = <0xa4>;
			};

			uart3-rts {
				rockchip,pins = <0x03 0x11 0x02 0x4c>;
				phandle = <0xa5>;
			};
		};

		uart4 {

			uart4-xfer {
				rockchip,pins = <0x00 0x1b 0x03 0x4b 0x00 0x1a 0x03 0x4c>;
				phandle = <0xa6>;
			};

			uart4-cts {
				rockchip,pins = <0x00 0x18 0x03 0x4c>;
				phandle = <0xa7>;
			};

			uart4-rts {
				rockchip,pins = <0x00 0x19 0x03 0x4c>;
				phandle = <0xa8>;
			};
		};

		pcfg-pull-none-drv-8ma {
			bias-disable;
			drive-strength = <0x08>;
			phandle = <0x49>;
		};

		pcfg-pull-up-drv-8ma {
			bias-pull-up;
			drive-strength = <0x08>;
			phandle = <0x4a>;
		};

		ir {

			ir-int {
				rockchip,pins = <0x03 0x1e 0x00 0x4b>;
				phandle = <0x53>;
			};
		};

		keys {

			pwr-key {
				rockchip,pins = <0x00 0x02 0x00 0x4b>;
				phandle = <0x50>;
			};
		};

		leds {

			stby-pwren {
				rockchip,pins = <0x00 0x0c 0x00 0x4c>;
				phandle = <0xa9>;
			};

			led-ctl {
				rockchip,pins = <0x03 0x1d 0x00 0x4c>;
				phandle = <0x52>;
			};
		};

		sdio {

			wifi-reg-on {
				rockchip,pins = <0x03 0x04 0x00 0x4c>;
				phandle = <0x56>;
			};

			bt-rst {
				rockchip,pins = <0x03 0x05 0x00 0x4c>;
				phandle = <0x55>;
			};
		};

		usb {

			host-vbus-drv {
				rockchip,pins = <0x00 0x04 0x00 0x4c>;
				phandle = <0x57>;
			};
		};
	};

	chosen {
		stdout-path = "serial2:115200n8";
	};

	memory {
		device_type = "memory";
		reg = <0x00 0x00 0x00 0x40000000>;
	};

	emmc-pwrseq {
		compatible = "mmc-pwrseq-emmc";
		pinctrl-0 = <0x4e>;
		pinctrl-names = "default";
		reset-gpios = <0x4f 0x03 0x00>;
		phandle = <0x11>;
	};

	gpio-keys {
		compatible = "gpio-keys";
		pinctrl-names = "default";
		pinctrl-0 = <0x50>;
		phandle = <0xaa>;

		power {
			wakeup-source;
			gpios = <0x51 0x02 0x01>;
			label = "GPIO Power";
			linux,code = <0x74>;
		};
	};

	gpio-leds {
		compatible = "gpio-leds";
		phandle = <0xab>;

		led-0 {
			gpios = <0x2e 0x1d 0x00>;
			label = "r88:green:led";
			pinctrl-names = "default";
			pinctrl-0 = <0x52>;
			phandle = <0xac>;
		};
	};

	ir-receiver {
		compatible = "gpio-ir-receiver";
		gpios = <0x2e 0x1e 0x01>;
		pinctrl-names = "default";
		pinctrl-0 = <0x53>;
		phandle = <0xad>;
	};

	sdio-pwrseq {
		compatible = "mmc-pwrseq-simple";
		clocks = <0x54>;
		clock-names = "ext_clock";
		pinctrl-names = "default";
		pinctrl-0 = <0x55 0x56>;
		reset-gpios = <0x2e 0x05 0x01 0x2e 0x04 0x01>;
		phandle = <0x0b>;
	};

	vcc18-regulator {
		compatible = "regulator-fixed";
		regulator-name = "vcc_18";
		regulator-min-microvolt = <0x1b7740>;
		regulator-max-microvolt = <0x1b7740>;
		regulator-always-on;
		regulator-boot-on;
		vin-supply = <0x31>;
		phandle = <0x15>;
	};

	vcc-host-regulator {
		compatible = "regulator-fixed";
		enable-active-high;
		gpio = <0x51 0x04 0x00>;
		pinctrl-names = "default";
		pinctrl-0 = <0x57>;
		regulator-name = "vcc_host";
		regulator-always-on;
		regulator-boot-on;
		vin-supply = <0x31>;
		phandle = <0xae>;
	};

	vcc-io-regulator {
		compatible = "regulator-fixed";
		regulator-name = "vcc_io";
		regulator-min-microvolt = <0x325aa0>;
		regulator-max-microvolt = <0x325aa0>;
		regulator-always-on;
		regulator-boot-on;
		vin-supply = <0x31>;
		phandle = <0x0f>;
	};

	vcc-lan-regulator {
		compatible = "regulator-fixed";
		regulator-name = "vcc_lan";
		regulator-min-microvolt = <0x325aa0>;
		regulator-max-microvolt = <0x325aa0>;
		regulator-always-on;
		regulator-boot-on;
		vin-supply = <0x0f>;
		phandle = <0x2d>;
	};

	vcc-sys-regulator {
		compatible = "regulator-fixed";
		regulator-name = "vcc_sys";
		regulator-min-microvolt = <0x4c4b40>;
		regulator-max-microvolt = <0x4c4b40>;
		regulator-always-on;
		regulator-boot-on;
		phandle = <0x31>;
	};

	vccio-wl-regulator {
		compatible = "regulator-fixed";
		regulator-name = "vccio_wl";
		regulator-min-microvolt = <0x325aa0>;
		regulator-max-microvolt = <0x325aa0>;
		regulator-always-on;
		regulator-boot-on;
		vin-supply = <0x0f>;
		phandle = <0x10>;
	};

	vdd-10-regulator {
		compatible = "regulator-fixed";
		regulator-name = "vdd_10";
		regulator-min-microvolt = <0xf4240>;
		regulator-max-microvolt = <0xf4240>;
		regulator-always-on;
		regulator-boot-on;
		vin-supply = <0x31>;
		phandle = <0xaf>;
	};

	__symbols__ {
		cpu_l0 = "/cpus/cpu@0";
		cpu_l1 = "/cpus/cpu@1";
		cpu_l2 = "/cpus/cpu@2";
		cpu_l3 = "/cpus/cpu@3";
		cpu_b0 = "/cpus/cpu@100";
		cpu_b1 = "/cpus/cpu@101";
		cpu_b2 = "/cpus/cpu@102";
		cpu_b3 = "/cpus/cpu@103";
		xin24m = "/oscillator";
		sdmmc = "/mmc@ff0c0000";
		sdio0 = "/mmc@ff0d0000";
		emmc = "/mmc@ff0f0000";
		saradc = "/saradc@ff100000";
		spi0 = "/spi@ff110000";
		spi1 = "/spi@ff120000";
		spi2 = "/spi@ff130000";
		i2c2 = "/i2c@ff140000";
		i2c3 = "/i2c@ff150000";
		i2c4 = "/i2c@ff160000";
		i2c5 = "/i2c@ff170000";
		uart0 = "/serial@ff180000";
		uart1 = "/serial@ff190000";
		uart3 = "/serial@ff1b0000";
		uart4 = "/serial@ff1c0000";
		dmac_peri = "/dma-controller@ff250000";
		cpu_thermal = "/thermal-zones/cpu-thermal";
		cpu_alert0 = "/thermal-zones/cpu-thermal/trips/cpu_alert0";
		cpu_alert1 = "/thermal-zones/cpu-thermal/trips/cpu_alert1";
		cpu_crit = "/thermal-zones/cpu-thermal/trips/cpu_crit";
		gpu_thermal = "/thermal-zones/gpu-thermal";
		gpu_alert0 = "/thermal-zones/gpu-thermal/trips/gpu_alert0";
		gpu_crit = "/thermal-zones/gpu-thermal/trips/gpu_crit";
		tsadc = "/tsadc@ff280000";
		gmac = "/ethernet@ff290000";
		usb_host0_ehci = "/usb@ff500000";
		usb_otg = "/usb@ff580000";
		dmac_bus = "/dma-controller@ff600000";
		i2c0 = "/i2c@ff650000";
		vdd_cpu = "/i2c@ff650000/syr827@40";
		hym8563 = "/i2c@ff650000/hym8563@51";
		i2c1 = "/i2c@ff660000";
		pwm0 = "/pwm@ff680000";
		pwm1 = "/pwm@ff680010";
		pwm2 = "/pwm@ff680020";
		pwm3 = "/pwm@ff680030";
		uart2 = "/serial@ff690000";
		mbox = "/mbox@ff6b0000";
		pmu = "/power-management@ff730000";
		power = "/power-management@ff730000/power-controller";
		pmugrf = "/syscon@ff738000";
		pmu_io_domains = "/syscon@ff738000/io-domains";
		cru = "/clock-controller@ff760000";
		grf = "/syscon@ff770000";
		io_domains = "/syscon@ff770000/io-domains";
		wdt = "/watchdog@ff800000";
		timer0 = "/timer@ff810000";
		spdif = "/spdif@ff880000";
		i2s_2ch = "/i2s-2ch@ff890000";
		i2s_8ch = "/i2s-8ch@ff898000";
		iep_mmu = "/iommu@ff900800";
		isp_mmu = "/iommu@ff914000";
		vop_mmu = "/iommu@ff930300";
		hevc_mmu = "/iommu@ff9a0440";
		vpu_mmu = "/iommu@ff9a0800";
		qos_iep = "/qos@ffad0000";
		qos_isp_r0 = "/qos@ffad0080";
		qos_isp_r1 = "/qos@ffad0100";
		qos_isp_w0 = "/qos@ffad0180";
		qos_isp_w1 = "/qos@ffad0200";
		qos_vip = "/qos@ffad0280";
		qos_vop = "/qos@ffad0300";
		qos_rga_r = "/qos@ffad0380";
		qos_rga_w = "/qos@ffad0400";
		qos_hevc_r = "/qos@ffae0000";
		qos_vpu_r = "/qos@ffae0100";
		qos_vpu_w = "/qos@ffae0180";
		qos_gpu = "/qos@ffaf0000";
		efuse256 = "/efuse@ffb00000";
		cpu_leakage = "/efuse@ffb00000/cpu-leakage@17";
		temp_adjust = "/efuse@ffb00000/temp-adjust@1f";
		gic = "/interrupt-controller@ffb71000";
		pinctrl = "/pinctrl";
		gpio0 = "/pinctrl/gpio@ff750000";
		gpio1 = "/pinctrl/gpio@ff780000";
		gpio2 = "/pinctrl/gpio@ff790000";
		gpio3 = "/pinctrl/gpio@ff7a0000";
		pcfg_pull_up = "/pinctrl/pcfg-pull-up";
		pcfg_pull_down = "/pinctrl/pcfg-pull-down";
		pcfg_pull_none = "/pinctrl/pcfg-pull-none";
		pcfg_pull_none_12ma = "/pinctrl/pcfg-pull-none-12ma";
		emmc_clk = "/pinctrl/emmc/emmc-clk";
		emmc_cmd = "/pinctrl/emmc/emmc-cmd";
		emmc_pwr = "/pinctrl/emmc/emmc-pwr";
		emmc_bus1 = "/pinctrl/emmc/emmc-bus1";
		emmc_bus4 = "/pinctrl/emmc/emmc-bus4";
		emmc_bus8 = "/pinctrl/emmc/emmc-bus8";
		emmc_reset = "/pinctrl/emmc/emmc-reset";
		rgmii_pins = "/pinctrl/gmac/rgmii-pins";
		rmii_pins = "/pinctrl/gmac/rmii-pins";
		i2c0_xfer = "/pinctrl/i2c0/i2c0-xfer";
		i2c1_xfer = "/pinctrl/i2c1/i2c1-xfer";
		i2c2_xfer = "/pinctrl/i2c2/i2c2-xfer";
		i2c3_xfer = "/pinctrl/i2c3/i2c3-xfer";
		i2c4_xfer = "/pinctrl/i2c4/i2c4-xfer";
		i2c5_xfer = "/pinctrl/i2c5/i2c5-xfer";
		i2s_8ch_bus = "/pinctrl/i2s/i2s-8ch-bus";
		pwm0_pin = "/pinctrl/pwm0/pwm0-pin";
		pwm1_pin = "/pinctrl/pwm1/pwm1-pin";
		pwm3_pin = "/pinctrl/pwm3/pwm3-pin";
		sdio0_bus1 = "/pinctrl/sdio0/sdio0-bus1";
		sdio0_bus4 = "/pinctrl/sdio0/sdio0-bus4";
		sdio0_cmd = "/pinctrl/sdio0/sdio0-cmd";
		sdio0_clk = "/pinctrl/sdio0/sdio0-clk";
		sdio0_cd = "/pinctrl/sdio0/sdio0-cd";
		sdio0_wp = "/pinctrl/sdio0/sdio0-wp";
		sdio0_pwr = "/pinctrl/sdio0/sdio0-pwr";
		sdio0_bkpwr = "/pinctrl/sdio0/sdio0-bkpwr";
		sdio0_int = "/pinctrl/sdio0/sdio0-int";
		sdmmc_clk = "/pinctrl/sdmmc/sdmmc-clk";
		sdmmc_cmd = "/pinctrl/sdmmc/sdmmc-cmd";
		sdmmc_cd = "/pinctrl/sdmmc/sdmmc-cd";
		sdmmc_bus1 = "/pinctrl/sdmmc/sdmmc-bus1";
		sdmmc_bus4 = "/pinctrl/sdmmc/sdmmc-bus4";
		spdif_tx = "/pinctrl/spdif/spdif-tx";
		spi0_clk = "/pinctrl/spi0/spi0-clk";
		spi0_cs0 = "/pinctrl/spi0/spi0-cs0";
		spi0_cs1 = "/pinctrl/spi0/spi0-cs1";
		spi0_tx = "/pinctrl/spi0/spi0-tx";
		spi0_rx = "/pinctrl/spi0/spi0-rx";
		spi1_clk = "/pinctrl/spi1/spi1-clk";
		spi1_cs0 = "/pinctrl/spi1/spi1-cs0";
		spi1_cs1 = "/pinctrl/spi1/spi1-cs1";
		spi1_rx = "/pinctrl/spi1/spi1-rx";
		spi1_tx = "/pinctrl/spi1/spi1-tx";
		spi2_clk = "/pinctrl/spi2/spi2-clk";
		spi2_cs0 = "/pinctrl/spi2/spi2-cs0";
		spi2_rx = "/pinctrl/spi2/spi2-rx";
		spi2_tx = "/pinctrl/spi2/spi2-tx";
		otp_pin = "/pinctrl/tsadc/otp-pin";
		otp_out = "/pinctrl/tsadc/otp-out";
		uart0_xfer = "/pinctrl/uart0/uart0-xfer";
		uart0_cts = "/pinctrl/uart0/uart0-cts";
		uart0_rts = "/pinctrl/uart0/uart0-rts";
		uart1_xfer = "/pinctrl/uart1/uart1-xfer";
		uart1_cts = "/pinctrl/uart1/uart1-cts";
		uart1_rts = "/pinctrl/uart1/uart1-rts";
		uart2_xfer = "/pinctrl/uart2/uart2-xfer";
		uart3_xfer = "/pinctrl/uart3/uart3-xfer";
		uart3_cts = "/pinctrl/uart3/uart3-cts";
		uart3_rts = "/pinctrl/uart3/uart3-rts";
		uart4_xfer = "/pinctrl/uart4/uart4-xfer";
		uart4_cts = "/pinctrl/uart4/uart4-cts";
		uart4_rts = "/pinctrl/uart4/uart4-rts";
		pcfg_pull_none_drv_8ma = "/pinctrl/pcfg-pull-none-drv-8ma";
		pcfg_pull_up_drv_8ma = "/pinctrl/pcfg-pull-up-drv-8ma";
		ir_int = "/pinctrl/ir/ir-int";
		pwr_key = "/pinctrl/keys/pwr-key";
		stby_pwren = "/pinctrl/leds/stby-pwren";
		led_ctl = "/pinctrl/leds/led-ctl";
		wifi_reg_on = "/pinctrl/sdio/wifi-reg-on";
		bt_rst = "/pinctrl/sdio/bt-rst";
		host_vbus_drv = "/pinctrl/usb/host-vbus-drv";
		emmc_pwrseq = "/emmc-pwrseq";
		keys = "/gpio-keys";
		leds = "/gpio-leds";
		work_led = "/gpio-leds/led-0";
		ir = "/ir-receiver";
		sdio_pwrseq = "/sdio-pwrseq";
		vcc_18 = "/vcc18-regulator";
		vcc_host = "/vcc-host-regulator";
		vcc_io = "/vcc-io-regulator";
		vcc_lan = "/vcc-lan-regulator";
		vcc_sys = "/vcc-sys-regulator";
		vccio_wl = "/vccio-wl-regulator";
		vdd_10 = "/vdd-10-regulator";
	};
};
